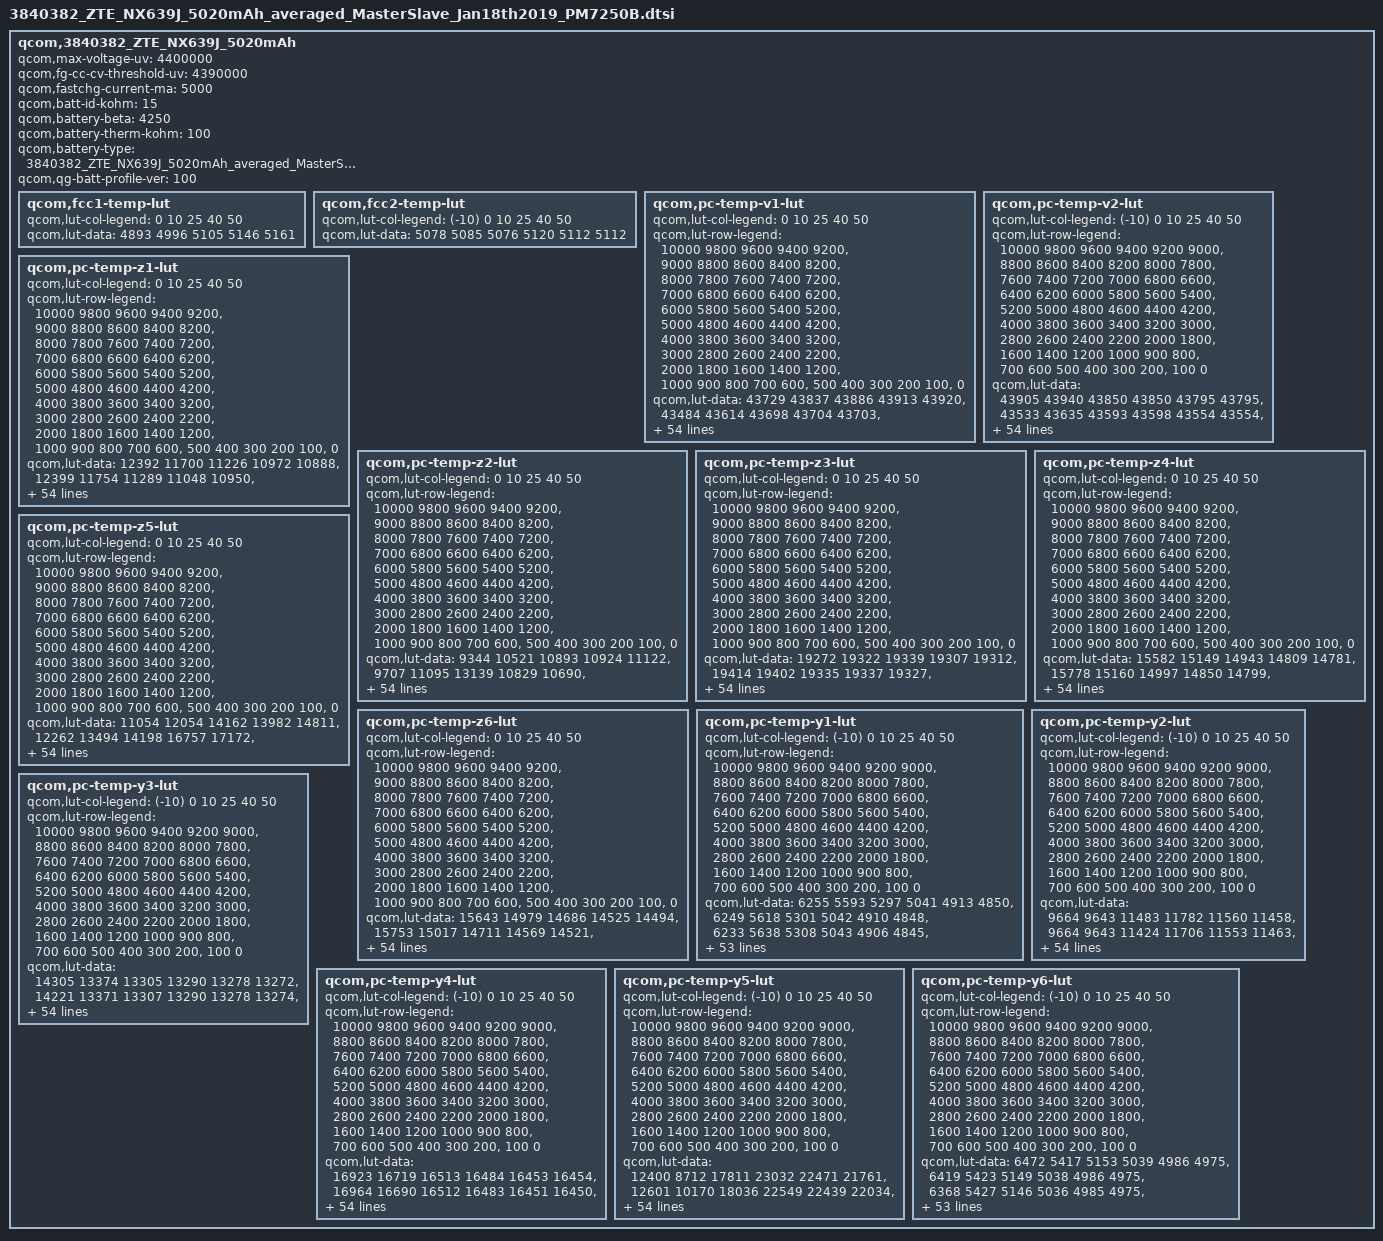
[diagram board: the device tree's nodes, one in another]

qcom,3840382_ZTE_NX639J_5020mAh {
    /* 3840382_ZTE_NX639J_5020mAh_averaged_MasterSlave_Jan18th2019 */
    qcom,max-voltage-uv = <4400000>;
    qcom,fg-cc-cv-threshold-uv = <4390000>;
    qcom,fastchg-current-ma = <5000>;
    qcom,batt-id-kohm = <15>;
    qcom,battery-beta = <4250>;
    qcom,battery-therm-kohm = <100>;
    qcom,battery-type = "3840382_ZTE_NX639J_5020mAh_averaged_MasterSlave_Jan18th2019";
    qcom,qg-batt-profile-ver = <100>;
    qcom,fcc1-temp-lut {
		qcom,lut-col-legend = <0 10 25 40 50>;
		qcom,lut-data = <4893 4996 5105 5146 5161>;
	};

	qcom,fcc2-temp-lut {
		qcom,lut-col-legend = <(-10) 0 10 25 40 50>;
		qcom,lut-data = <5078 5085 5076 5120 5112 5112>;
	};

	qcom,pc-temp-v1-lut {
		qcom,lut-col-legend = <0 10 25 40 50>;
		qcom,lut-row-legend = <10000 9800 9600 9400 9200>,
			<9000 8800 8600 8400 8200>,
			<8000 7800 7600 7400 7200>,
			<7000 6800 6600 6400 6200>,
			<6000 5800 5600 5400 5200>,
			<5000 4800 4600 4400 4200>,
			<4000 3800 3600 3400 3200>,
			<3000 2800 2600 2400 2200>,
			<2000 1800 1600 1400 1200>,
			<1000 900 800 700 600>,
			<500 400 300 200 100>,
			<0>;
		qcom,lut-data = <43729 43837 43886 43913 43920>,
			<43484 43614 43698 43704 43703>,
			<43234 43383 43471 43483 43490>,
			<42978 43142 43225 43257 43267>,
			<42731 42890 42983 43027 43040>,
			<42498 42647 42738 42791 42808>,
			<42275 42422 42498 42555 42574>,
			<42058 42205 42263 42319 42340>,
			<41849 41983 42034 42086 42107>,
			<41645 41759 41810 41854 41875>,
			<41454 41543 41591 41624 41645>,
			<41266 41344 41378 41399 41419>,
			<41065 41150 41178 41178 41199>,
			<40852 40948 40977 40963 40986>,
			<40623 40738 40752 40752 40777>,
			<40351 40513 40516 40547 40572>,
			<40063 40238 40300 40352 40374>,
			<39861 39979 40100 40170 40188>,
			<39730 39821 39922 39997 40009>,
			<39616 39713 39781 39832 39840>,
			<39494 39597 39650 39675 39682>,
			<39375 39454 39458 39484 39499>,
			<39256 39293 39164 39199 39236>,
			<39137 39096 38916 38937 38981>,
			<39019 38852 38766 38798 38828>,
			<38900 38666 38652 38698 38716>,
			<38779 38554 38562 38603 38613>,
			<38667 38469 38492 38509 38514>,
			<38563 38402 38426 38422 38421>,
			<38468 38347 38360 38340 38328>,
			<38400 38299 38298 38265 38240>,
			<38347 38254 38240 38195 38167>,
			<38301 38213 38186 38132 38106>,
			<38260 38176 38137 38072 38047>,
			<38223 38143 38093 38019 37987>,
			<38192 38108 38052 37970 37928>,
			<38169 38076 38012 37921 37869>,
			<38141 38041 37972 37876 37814>,
			<38092 37988 37917 37817 37747>,
			<38016 37907 37829 37729 37656>,
			<37925 37810 37723 37622 37550>,
			<37805 37698 37609 37509 37437>,
			<37667 37567 37478 37381 37308>,
			<37507 37404 37318 37224 37147>,
			<37356 37268 37173 37081 37008>,
			<37246 37177 37082 36991 36929>,
			<37209 37142 37055 36967 36907>,
			<37182 37119 37043 36951 36889>,
			<37158 37101 37025 36933 36869>,
			<37122 37067 36984 36885 36815>,
			<36951 36886 36775 36651 36558>,
			<36525 36462 36353 36221 36122>,
			<35958 35893 35785 35649 35548>,
			<35187 35119 35008 34867 34764>,
			<33977 33913 33804 33658 33549>,
			<30000 30000 30000 30000 30000>;
	};

	qcom,pc-temp-v2-lut {
		qcom,lut-col-legend = <(-10) 0 10 25 40 50>;
		qcom,lut-row-legend = <10000 9800 9600 9400 9200 9000>,
			<8800 8600 8400 8200 8000 7800>,
			<7600 7400 7200 7000 6800 6600>,
			<6400 6200 6000 5800 5600 5400>,
			<5200 5000 4800 4600 4400 4200>,
			<4000 3800 3600 3400 3200 3000>,
			<2800 2600 2400 2200 2000 1800>,
			<1600 1400 1200 1000 900 800>,
			<700 600 500 400 300 200>,
			<100 0>;
		qcom,lut-data = <43905 43940 43850 43850 43795 43795>,
			<43533 43635 43593 43598 43554 43554>,
			<43185 43346 43340 43350 43315 43315>,
			<42862 43075 43092 43106 43077 43078>,
			<42561 42822 42846 42865 42841 42845>,
			<42283 42575 42605 42625 42605 42611>,
			<42024 42329 42367 42389 42370 42375>,
			<41784 42091 42134 42154 42135 42139>,
			<41551 41868 41910 41924 41904 41907>,
			<41319 41655 41692 41698 41675 41679>,
			<41163 41448 41476 41473 41448 41453>,
			<41098 41241 41255 41246 41224 41231>,
			<41035 41042 41040 41029 41006 41012>,
			<40769 40868 40859 40847 40802 40801>,
			<40127 40715 40701 40685 40606 40595>,
			<39682 40502 40507 40481 40407 40395>,
			<39497 40092 40203 40182 40196 40202>,
			<39353 39679 39888 39913 39995 40017>,
			<39185 39473 39680 39774 39826 39847>,
			<39012 39337 39519 39671 39672 39684>,
			<38852 39191 39347 39512 39486 39493>,
			<38699 39022 39144 39251 39244 39256>,
			<38563 38857 38950 38998 39013 39028>,
			<38452 38705 38789 38815 38829 38842>,
			<38357 38561 38648 38659 38669 38678>,
			<38274 38435 38523 38528 38536 38542>,
			<38202 38322 38412 38416 38424 38429>,
			<38137 38224 38312 38316 38324 38327>,
			<38076 38141 38219 38225 38231 38232>,
			<38019 38069 38133 38143 38145 38144>,
			<37964 38007 38055 38067 38069 38067>,
			<37913 37954 37983 37996 38000 37997>,
			<37861 37905 37917 37929 37933 37930>,
			<37804 37857 37858 37866 37869 37867>,
			<37746 37812 37805 37806 37805 37802>,
			<37685 37765 37759 37749 37724 37713>,
			<37620 37717 37723 37693 37630 37597>,
			<37553 37664 37684 37631 37540 37491>,
			<37484 37605 37629 37562 37460 37403>,
			<37414 37539 37562 37486 37381 37319>,
			<37344 37459 37484 37405 37297 37236>,
			<37274 37358 37388 37312 37207 37149>,
			<37203 37249 37272 37193 37089 37036>,
			<37127 37137 37134 37056 36954 36902>,
			<37045 37041 37010 36929 36842 36788>,
			<36941 36957 36947 36884 36814 36758>,
			<36883 36919 36928 36869 36801 36748>,
			<36805 36879 36908 36850 36784 36733>,
			<36704 36825 36882 36820 36750 36702>,
			<36547 36728 36817 36741 36626 36589>,
			<36302 36514 36600 36469 36268 36251>,
			<35914 36102 36123 35979 35740 35741>,
			<35336 35497 35479 35326 35039 35066>,
			<34464 34628 34608 34410 33998 34109>,
			<32987 33305 33297 32979 32712 32726>,
			<28469 28082 28052 28053 28037 28038>;
	};

	qcom,pc-temp-z1-lut {
		qcom,lut-col-legend = <0 10 25 40 50>;
		qcom,lut-row-legend = <10000 9800 9600 9400 9200>,
			<9000 8800 8600 8400 8200>,
			<8000 7800 7600 7400 7200>,
			<7000 6800 6600 6400 6200>,
			<6000 5800 5600 5400 5200>,
			<5000 4800 4600 4400 4200>,
			<4000 3800 3600 3400 3200>,
			<3000 2800 2600 2400 2200>,
			<2000 1800 1600 1400 1200>,
			<1000 900 800 700 600>,
			<500 400 300 200 100>,
			<0>;
		qcom,lut-data = <12392 11700 11226 10972 10888>,
			<12399 11754 11289 11048 10950>,
			<12398 11782 11290 11047 10954>,
			<12395 11778 11285 11049 10954>,
			<12393 11759 11281 11048 10953>,
			<12395 11748 11277 11042 10950>,
			<12398 11747 11271 11035 10946>,
			<12394 11746 11264 11030 10943>,
			<12387 11747 11258 11025 10940>,
			<12380 11751 11257 11022 10938>,
			<12378 11753 11257 11019 10937>,
			<12378 11743 11257 11017 10937>,
			<12371 11726 11256 11019 10937>,
			<12353 11706 11254 11022 10937>,
			<12331 11680 11246 11021 10937>,
			<12310 11669 11232 11015 10937>,
			<12289 11669 11228 11012 10938>,
			<12277 11668 11229 11013 10939>,
			<12272 11671 11231 11015 10939>,
			<12268 11678 11234 11017 10940>,
			<12258 11683 11239 11019 10942>,
			<12242 11687 11242 11020 10942>,
			<12230 11691 11244 11021 10943>,
			<12225 11693 11246 11023 10943>,
			<12222 11691 11249 11024 10945>,
			<12227 11690 11253 11026 10947>,
			<12238 11690 11258 11028 10949>,
			<12247 11691 11265 11031 10951>,
			<12252 11694 11270 11034 10954>,
			<12257 11700 11273 11037 10957>,
			<12259 11706 11276 11041 10960>,
			<12258 11709 11276 11044 10964>,
			<12257 11712 11276 11047 10968>,
			<12267 11717 11277 11051 10972>,
			<12287 11727 11286 11055 10975>,
			<12294 11734 11297 11061 10978>,
			<12301 11744 11298 11065 10980>,
			<12306 11756 11296 11069 10983>,
			<12309 11763 11296 11072 10986>,
			<12317 11776 11302 11075 10990>,
			<12322 11782 11308 11077 10993>,
			<12339 11776 11310 11081 10996>,
			<12349 11771 11314 11087 10999>,
			<12370 11881 11323 11092 11003>,
			<12380 11852 11330 11096 11007>,
			<12366 11804 11331 11098 11009>,
			<12362 11800 11327 11103 11009>,
			<12389 11808 11336 11103 11012>,
			<12373 11793 11332 11105 11015>,
			<12348 11821 11334 11110 11019>,
			<12378 11828 11339 11115 11024>,
			<12406 11824 11353 11121 11032>,
			<12413 11876 11377 11131 11038>,
			<12450 11875 11389 11147 11054>,
			<12450 11875 11389 11147 11054>,
			<12450 11875 11389 11147 11054>;
	};

	qcom,pc-temp-z2-lut {
		qcom,lut-col-legend = <0 10 25 40 50>;
		qcom,lut-row-legend = <10000 9800 9600 9400 9200>,
			<9000 8800 8600 8400 8200>,
			<8000 7800 7600 7400 7200>,
			<7000 6800 6600 6400 6200>,
			<6000 5800 5600 5400 5200>,
			<5000 4800 4600 4400 4200>,
			<4000 3800 3600 3400 3200>,
			<3000 2800 2600 2400 2200>,
			<2000 1800 1600 1400 1200>,
			<1000 900 800 700 600>,
			<500 400 300 200 100>,
			<0>;
		qcom,lut-data = <9344 10521 10893 10924 11122>,
			<9707 11095 13139 10829 10690>,
			<9815 11376 12742 10880 10780>,
			<10143 11290 12028 10924 10844>,
			<10345 10830 11482 10932 10868>,
			<10350 10566 10979 10880 10820>,
			<10353 10641 10781 10811 10750>,
			<10354 10750 10967 10750 10695>,
			<10353 10724 11188 10693 10642>,
			<10351 10563 11185 10681 10623>,
			<10345 10473 11129 10690 10627>,
			<10335 10477 11058 10696 10631>,
			<10323 10484 10867 10703 10586>,
			<10301 10491 10707 10716 10509>,
			<10277 10504 10723 10729 10495>,
			<10254 10520 10761 10746 10525>,
			<10233 10549 10774 10753 10553>,
			<10230 10585 10772 10691 10566>,
			<10253 10621 10771 10615 10578>,
			<10282 10660 10793 10625 10602>,
			<10304 10686 10833 10687 10643>,
			<10325 10703 10851 10737 10660>,
			<10345 10713 10859 10782 10651>,
			<10362 10712 10863 10812 10641>,
			<10378 10701 10836 10767 10649>,
			<10397 10695 10792 10660 10677>,
			<10422 10708 10783 10632 10706>,
			<10446 10726 10794 10665 10736>,
			<10468 10728 10811 10714 10771>,
			<10490 10728 10848 10785 10833>,
			<10510 10728 10893 10865 10905>,
			<10527 10733 10918 10883 10888>,
			<10545 10745 10937 10860 10674>,
			<10573 10760 10943 10839 10529>,
			<10603 10783 10943 10821 10544>,
			<10570 10803 10942 10803 10578>,
			<10229 10817 10949 10815 10617>,
			<9930 10829 10972 10874 10672>,
			<10035 10844 10998 10930 10721>,
			<10314 10863 11036 10980 10762>,
			<10431 10885 11066 11015 10795>,
			<10424 10912 11075 11000 10811>,
			<10423 10944 11081 10968 10821>,
			<10485 10978 11091 10973 10837>,
			<10357 11243 11160 10985 10850>,
			<10423 17295 11253 10985 10828>,
			<10595 11767 11243 10965 10816>,
			<10419 11943 11195 10987 10839>,
			<10440 11686 11234 10998 10879>,
			<10396 11827 11279 11092 11075>,
			<10252 11537 11384 11105 10861>,
			<10053 11168 11382 10885 10617>,
			<9945 11270 11354 10786 10548>,
			<9751 16042 11240 10717 10470>,
			<9751 16042 11240 10717 10470>,
			<9751 16042 11240 10717 10470>;
	};

	qcom,pc-temp-z3-lut {
		qcom,lut-col-legend = <0 10 25 40 50>;
		qcom,lut-row-legend = <10000 9800 9600 9400 9200>,
			<9000 8800 8600 8400 8200>,
			<8000 7800 7600 7400 7200>,
			<7000 6800 6600 6400 6200>,
			<6000 5800 5600 5400 5200>,
			<5000 4800 4600 4400 4200>,
			<4000 3800 3600 3400 3200>,
			<3000 2800 2600 2400 2200>,
			<2000 1800 1600 1400 1200>,
			<1000 900 800 700 600>,
			<500 400 300 200 100>,
			<0>;
		qcom,lut-data = <19272 19322 19339 19307 19312>,
			<19414 19402 19335 19337 19327>,
			<19502 19462 19372 19362 19347>,
			<19636 19501 19414 19375 19361>,
			<19705 19539 19427 19381 19369>,
			<19701 19555 19432 19384 19372>,
			<19694 19549 19437 19385 19373>,
			<19687 19541 19446 19385 19374>,
			<19680 19539 19454 19385 19374>,
			<19674 19540 19453 19383 19374>,
			<19668 19539 19447 19379 19371>,
			<19660 19537 19440 19376 19367>,
			<19656 19532 19426 19373 19360>,
			<19656 19524 19414 19372 19353>,
			<19659 19511 19411 19369 19350>,
			<19679 19504 19408 19365 19348>,
			<19712 19506 19405 19361 19347>,
			<19719 19508 19399 19355 19344>,
			<19688 19500 19392 19349 19341>,
			<19652 19481 19389 19346 19338>,
			<19636 19471 19386 19344 19334>,
			<19625 19476 19387 19343 19332>,
			<19621 19484 19395 19347 19332>,
			<19624 19492 19400 19351 19332>,
			<19629 19500 19397 19346 19327>,
			<19632 19504 19391 19333 19316>,
			<19638 19504 19386 19329 19312>,
			<19641 19504 19382 19330 19317>,
			<19640 19503 19381 19331 19325>,
			<19637 19500 19383 19338 19340>,
			<19634 19496 19386 19350 19361>,
			<19624 19492 19390 19357 19365>,
			<19613 19487 19396 19363 19358>,
			<19603 19484 19398 19365 19350>,
			<19591 19480 19398 19362 19345>,
			<19556 19477 19397 19357 19341>,
			<19403 19473 19395 19353 19338>,
			<19272 19469 19390 19348 19335>,
			<19263 19467 19386 19345 19333>,
			<19261 19465 19384 19343 19330>,
			<19261 19462 19382 19341 19329>,
			<19261 19454 19379 19340 19329>,
			<19261 19445 19377 19339 19330>,
			<19260 19441 19374 19339 19334>,
			<19261 19383 19367 19336 19335>,
			<19260 19279 19356 19330 19325>,
			<19260 19293 19355 19328 19320>,
			<19260 19285 19336 19324 19316>,
			<19260 19268 19331 19322 19314>,
			<19260 19267 19332 19316 19303>,
			<19261 19260 19327 19319 19323>,
			<19262 19261 19320 19333 19334>,
			<19263 19275 19320 19336 19335>,
			<19265 19273 19318 19336 19335>,
			<19265 19273 19318 19336 19335>,
			<19265 19273 19318 19336 19335>;
	};

	qcom,pc-temp-z4-lut {
		qcom,lut-col-legend = <0 10 25 40 50>;
		qcom,lut-row-legend = <10000 9800 9600 9400 9200>,
			<9000 8800 8600 8400 8200>,
			<8000 7800 7600 7400 7200>,
			<7000 6800 6600 6400 6200>,
			<6000 5800 5600 5400 5200>,
			<5000 4800 4600 4400 4200>,
			<4000 3800 3600 3400 3200>,
			<3000 2800 2600 2400 2200>,
			<2000 1800 1600 1400 1200>,
			<1000 900 800 700 600>,
			<500 400 300 200 100>,
			<0>;
		qcom,lut-data = <15582 15149 14943 14809 14781>,
			<15778 15160 14997 14850 14799>,
			<15747 15154 14969 14870 14828>,
			<15577 15116 14921 14838 14807>,
			<15421 15017 14881 14809 14785>,
			<15319 14934 14841 14784 14765>,
			<15233 14879 14804 14761 14746>,
			<15161 14833 14762 14742 14729>,
			<15099 14803 14724 14725 14714>,
			<15046 14780 14703 14711 14702>,
			<15003 14761 14688 14697 14690>,
			<14967 14744 14681 14687 14682>,
			<14937 14730 14682 14681 14680>,
			<14913 14721 14685 14677 14678>,
			<14891 14714 14683 14672 14675>,
			<14868 14710 14681 14668 14668>,
			<14846 14708 14679 14664 14662>,
			<14830 14706 14675 14660 14657>,
			<14818 14701 14670 14657 14654>,
			<14807 14690 14660 14654 14652>,
			<14794 14680 14649 14652 14651>,
			<14781 14672 14657 14654 14652>,
			<14766 14666 14719 14710 14701>,
			<14748 14679 14765 14767 14759>,
			<14730 14729 14774 14773 14768>,
			<14720 14756 14779 14774 14771>,
			<14712 14753 14777 14772 14770>,
			<14710 14747 14764 14762 14756>,
			<14712 14739 14749 14746 14733>,
			<14717 14726 14734 14726 14706>,
			<14717 14714 14719 14703 14674>,
			<14713 14703 14704 14685 14662>,
			<14709 14694 14690 14669 14658>,
			<14707 14685 14680 14661 14656>,
			<14705 14676 14673 14660 14656>,
			<14721 14669 14667 14660 14656>,
			<14875 14662 14664 14660 14657>,
			<15011 14657 14661 14659 14657>,
			<15012 14655 14661 14659 14658>,
			<14999 14654 14666 14666 14666>,
			<14987 14654 14670 14674 14674>,
			<14980 14656 14667 14671 14671>,
			<14969 14658 14661 14666 14664>,
			<14951 14656 14661 14666 14664>,
			<14881 14688 14656 14662 14659>,
			<14851 14771 14639 14645 14644>,
			<14849 14755 14632 14639 14642>,
			<14846 14758 14642 14631 14632>,
			<14843 14771 14639 14618 14618>,
			<14836 14770 14635 14622 14623>,
			<14837 14782 14655 14642 14632>,
			<14851 14792 14674 14637 14632>,
			<14861 14784 14676 14637 14634>,
			<14873 14792 14684 14640 14637>,
			<14873 14792 14684 14640 14637>,
			<14873 14792 14684 14640 14637>;
	};

	qcom,pc-temp-z5-lut {
		qcom,lut-col-legend = <0 10 25 40 50>;
		qcom,lut-row-legend = <10000 9800 9600 9400 9200>,
			<9000 8800 8600 8400 8200>,
			<8000 7800 7600 7400 7200>,
			<7000 6800 6600 6400 6200>,
			<6000 5800 5600 5400 5200>,
			<5000 4800 4600 4400 4200>,
			<4000 3800 3600 3400 3200>,
			<3000 2800 2600 2400 2200>,
			<2000 1800 1600 1400 1200>,
			<1000 900 800 700 600>,
			<500 400 300 200 100>,
			<0>;
		qcom,lut-data = <11054 12054 14162 13982 14811>,
			<12262 13494 14198 16757 17172>,
			<13276 14899 15689 18680 18910>,
			<14678 16344 17583 19757 20502>,
			<15560 18405 18841 20414 21477>,
			<15791 19495 19831 20802 21908>,
			<15947 18910 21195 21167 22277>,
			<16175 18066 23874 21672 22864>,
			<16491 18626 26769 22279 23629>,
			<16761 20988 28594 23041 24505>,
			<17008 23147 30039 24102 25783>,
			<17238 24789 30695 25196 26621>,
			<17329 26012 29623 26286 26027>,
			<17531 26040 28354 27369 24837>,
			<17920 25248 29128 28383 24784>,
			<20350 25173 31021 29747 26397>,
			<24644 27690 31440 30412 28180>,
			<25801 30404 29583 28925 29569>,
			<23194 30101 28032 27104 30798>,
			<20634 27916 30101 27799 31599>,
			<20535 26847 35525 30456 32224>,
			<20965 32770 43094 33245 32427>,
			<21589 43226 56260 36617 31749>,
			<23838 53293 63628 38937 30332>,
			<27740 64717 55530 34789 26840>,
			<33201 65535 41599 24689 20451>,
			<41573 65535 34468 20587 18046>,
			<48406 59133 29760 19495 17891>,
			<53404 54109 28018 19049 17989>,
			<57120 49571 28259 20135 22438>,
			<57097 46259 28846 22940 31092>,
			<52948 43850 30745 26772 33303>,
			<47809 42236 36075 33408 33234>,
			<43609 42171 41551 38855 33233>,
			<39063 42793 47810 42260 35147>,
			<32515 43222 52539 44497 37878>,
			<20556 42963 53047 44270 38237>,
			<11895 42572 52630 42210 37906>,
			<11542 43206 51767 39739 37264>,
			<11549 45965 49257 36584 33472>,
			<11560 47590 45889 33292 29175>,
			<11590 40725 42265 30699 28148>,
			<11639 34273 38888 28759 27753>,
			<11723 35731 37531 28226 29956>,
			<12151 25798 36840 28193 31413>,
			<12288 12990 36444 28369 27342>,
			<12253 13365 37097 27776 23902>,
			<12236 13000 23813 27311 24649>,
			<12202 12432 22119 31611 30152>,
			<12227 12421 23535 26969 22271>,
			<12324 12331 20262 21473 26310>,
			<12332 12293 16911 23553 26555>,
			<12193 12607 16390 23329 24558>,
			<12100 12428 15502 21318 21600>,
			<12100 12428 15502 21318 21600>,
			<12100 12428 15502 21318 21600>;
	};

	qcom,pc-temp-z6-lut {
		qcom,lut-col-legend = <0 10 25 40 50>;
		qcom,lut-row-legend = <10000 9800 9600 9400 9200>,
			<9000 8800 8600 8400 8200>,
			<8000 7800 7600 7400 7200>,
			<7000 6800 6600 6400 6200>,
			<6000 5800 5600 5400 5200>,
			<5000 4800 4600 4400 4200>,
			<4000 3800 3600 3400 3200>,
			<3000 2800 2600 2400 2200>,
			<2000 1800 1600 1400 1200>,
			<1000 900 800 700 600>,
			<500 400 300 200 100>,
			<0>;
		qcom,lut-data = <15643 14979 14686 14525 14494>,
			<15753 15017 14711 14569 14521>,
			<15746 15032 14710 14586 14543>,
			<15699 15022 14709 14580 14542>,
			<15647 14985 14702 14574 14539>,
			<15583 14949 14680 14564 14533>,
			<15511 14915 14661 14553 14524>,
			<15454 14882 14645 14544 14517>,
			<15406 14861 14630 14536 14511>,
			<15364 14846 14618 14528 14505>,
			<15328 14832 14607 14519 14498>,
			<15295 14820 14598 14512 14492>,
			<15265 14807 14591 14509 14487>,
			<15236 14791 14585 14506 14483>,
			<15214 14772 14579 14503 14478>,
			<15203 14761 14573 14497 14475>,
			<15194 14758 14568 14492 14471>,
			<15181 14755 14563 14487 14468>,
			<15155 14748 14559 14483 14464>,
			<15128 14735 14553 14480 14462>,
			<15109 14729 14549 14478 14459>,
			<15094 14730 14553 14479 14459>,
			<15083 14734 14585 14506 14481>,
			<15074 14745 14608 14533 14505>,
			<15068 14773 14609 14532 14506>,
			<15066 14787 14610 14527 14504>,
			<15066 14786 14608 14523 14500>,
			<15067 14786 14602 14520 14497>,
			<15069 14784 14595 14516 14493>,
			<15072 14778 14591 14513 14491>,
			<15072 14772 14587 14509 14489>,
			<15066 14767 14584 14506 14486>,
			<15060 14762 14582 14503 14480>,
			<15055 14758 14580 14501 14476>,
			<15051 14754 14578 14499 14474>,
			<15046 14751 14576 14497 14472>,
			<15040 14749 14574 14495 14471>,
			<15035 14748 14573 14493 14469>,
			<15036 14749 14572 14492 14469>,
			<15037 14752 14575 14494 14471>,
			<15039 14754 14577 14497 14474>,
			<15043 14755 14576 14496 14473>,
			<15046 14756 14575 14494 14472>,
			<15047 14758 14576 14495 14474>,
			<15028 14748 14573 14493 14473>,
			<15019 14736 14563 14483 14462>,
			<15018 14735 14560 14480 14458>,
			<15018 14733 14555 14474 14452>,
			<15019 14733 14552 14468 14445>,
			<15019 14736 14552 14468 14443>,
			<15030 14742 14562 14479 14458>,
			<15044 14753 14569 14487 14466>,
			<15060 14764 14575 14491 14469>,
			<15086 14779 14584 14496 14474>,
			<15086 14779 14584 14496 14474>,
			<15086 14779 14584 14496 14474>;
	};

	qcom,pc-temp-y1-lut {
		qcom,lut-col-legend = <(-10) 0 10 25 40 50>;
		qcom,lut-row-legend = <10000 9800 9600 9400 9200 9000>,
			<8800 8600 8400 8200 8000 7800>,
			<7600 7400 7200 7000 6800 6600>,
			<6400 6200 6000 5800 5600 5400>,
			<5200 5000 4800 4600 4400 4200>,
			<4000 3800 3600 3400 3200 3000>,
			<2800 2600 2400 2200 2000 1800>,
			<1600 1400 1200 1000 900 800>,
			<700 600 500 400 300 200>,
			<100 0>;
		qcom,lut-data = <6255 5593 5297 5041 4913 4850>,
			<6249 5618 5301 5042 4910 4848>,
			<6233 5638 5308 5043 4906 4845>,
			<6213 5652 5314 5043 4903 4843>,
			<6196 5661 5319 5042 4900 4841>,
			<6189 5664 5321 5041 4897 4839>,
			<6183 5657 5319 5038 4895 4837>,
			<6174 5648 5317 5034 4893 4835>,
			<6168 5647 5314 5033 4891 4833>,
			<6158 5647 5308 5033 4888 4831>,
			<6153 5648 5304 5033 4887 4830>,
			<6176 5646 5301 5029 4885 4830>,
			<6204 5645 5299 5026 4884 4830>,
			<6206 5645 5299 5025 4883 4829>,
			<6196 5648 5302 5024 4882 4828>,
			<6192 5651 5305 5025 4882 4828>,
			<6202 5658 5309 5028 4883 4828>,
			<6214 5665 5312 5031 4883 4828>,
			<6211 5672 5313 5030 4883 4828>,
			<6198 5679 5312 5027 4881 4829>,
			<6192 5681 5312 5027 4881 4830>,
			<6191 5680 5314 5029 4882 4830>,
			<6191 5678 5316 5031 4883 4830>,
			<6186 5674 5315 5031 4883 4831>,
			<6177 5668 5312 5029 4883 4832>,
			<6174 5664 5310 5029 4884 4832>,
			<6175 5661 5309 5030 4886 4834>,
			<6175 5660 5309 5031 4888 4835>,
			<6186 5662 5310 5032 4890 4837>,
			<6214 5666 5312 5033 4892 4840>,
			<6222 5669 5312 5035 4894 4842>,
			<6204 5675 5312 5037 4895 4843>,
			<6188 5679 5312 5040 4897 4844>,
			<6197 5675 5314 5045 4901 4846>,
			<6218 5668 5319 5051 4904 4848>,
			<6224 5668 5320 5051 4904 4850>,
			<6213 5671 5317 5049 4903 4852>,
			<6198 5673 5314 5048 4903 4853>,
			<6184 5671 5315 5050 4906 4855>,
			<6171 5668 5315 5052 4910 4856>,
			<6170 5669 5316 5054 4912 4858>,
			<6181 5671 5318 5056 4913 4860>,
			<6185 5678 5322 5057 4915 4862>,
			<6187 5693 5333 5060 4918 4864>,
			<6226 5681 5336 5063 4923 4867>,
			<6194 5690 5332 5068 4927 4871>,
			<6222 5705 5329 5069 4929 4870>,
			<6266 5694 5331 5077 4927 4870>,
			<6235 5697 5333 5071 4929 4870>,
			<6224 5709 5337 5073 4931 4871>,
			<6246 5705 5346 5076 4933 4874>,
			<6277 5734 5349 5086 4936 4880>,
			<6286 5733 5363 5097 4949 4886>,
			<6371 5750 5382 5125 4961 4895>,
			<6371 5750 5382 5125 4961 4895>,
			<6371 5750 5382 5125 4961 4895>;
	};

	qcom,pc-temp-y2-lut {
		qcom,lut-col-legend = <(-10) 0 10 25 40 50>;
		qcom,lut-row-legend = <10000 9800 9600 9400 9200 9000>,
			<8800 8600 8400 8200 8000 7800>,
			<7600 7400 7200 7000 6800 6600>,
			<6400 6200 6000 5800 5600 5400>,
			<5200 5000 4800 4600 4400 4200>,
			<4000 3800 3600 3400 3200 3000>,
			<2800 2600 2400 2200 2000 1800>,
			<1600 1400 1200 1000 900 800>,
			<700 600 500 400 300 200>,
			<100 0>;
		qcom,lut-data = <9664 9643 11483 11782 11560 11458>,
			<9664 9643 11424 11706 11553 11463>,
			<9664 9643 11366 11627 11526 11450>,
			<9664 10059 11312 11553 11490 11425>,
			<9665 10521 11265 11490 11456 11397>,
			<9665 10707 11230 11448 11432 11373>,
			<9666 10718 11202 11420 11377 11314>,
			<9667 10724 11182 11400 11315 11246>,
			<9667 10734 11170 11387 11295 11224>,
			<9667 10748 11161 11377 11266 11212>,
			<9667 10768 11158 11370 11253 11202>,
			<9668 10806 11165 11364 11255 11182>,
			<9669 10859 11178 11359 11261 11163>,
			<9669 10942 11204 11355 11283 11160>,
			<9668 11073 11256 11353 11330 11165>,
			<9667 11130 11302 11362 11362 11175>,
			<9667 11116 11336 11444 11379 11194>,
			<9668 11100 11365 11555 11403 11224>,
			<9667 11116 11383 11661 11491 11308>,
			<9667 11157 11397 11762 11639 11437>,
			<9667 11187 11418 11776 11677 11474>,
			<9667 11205 11461 11702 11650 11473>,
			<9667 11219 11513 11646 11622 11472>,
			<9667 11070 11562 11653 11607 11479>,
			<9667 10721 11612 11672 11595 11491>,
			<9666 10559 11646 11698 11596 11500>,
			<9666 10214 11671 11745 11624 11515>,
			<9666 9887 11685 11787 11647 11532>,
			<9666 9821 11686 11821 11658 11553>,
			<9666 9787 11685 11847 11672 11580>,
			<9666 9765 11684 11861 11702 11606>,
			<9666 9746 11683 11875 11778 11632>,
			<9665 9733 11683 11881 11832 11665>,
			<9665 9726 11689 11858 11854 11730>,
			<9664 9720 11699 11829 11867 11788>,
			<9664 9715 11697 11826 11857 11761>,
			<9664 9709 11664 11829 11815 11651>,
			<9664 9703 11628 11827 11775 11592>,
			<9664 9698 11611 11798 11744 11578>,
			<9663 9694 11595 11767 11714 11570>,
			<9663 9689 11570 11751 11674 11552>,
			<9663 9685 11526 11729 11633 11525>,
			<9663 9681 11469 11703 11625 11516>,
			<9662 9678 11398 11644 11643 11512>,
			<9662 9675 11344 11596 11626 11486>,
			<9662 9673 11285 11495 11509 11293>,
			<9661 9672 11197 11502 11473 11235>,
			<9662 9670 11162 11455 11492 11239>,
			<9661 9669 11136 11423 11512 11276>,
			<9661 9667 11115 11436 11510 11230>,
			<9661 9666 11072 11372 11412 11208>,
			<9660 9665 10908 11247 11289 11130>,
			<9658 9663 10498 11103 11189 11009>,
			<9655 9661 10582 10969 11065 10831>,
			<9655 9661 10582 10969 11065 10831>,
			<9655 9661 10582 10969 11065 10831>;
	};

	qcom,pc-temp-y3-lut {
		qcom,lut-col-legend = <(-10) 0 10 25 40 50>;
		qcom,lut-row-legend = <10000 9800 9600 9400 9200 9000>,
			<8800 8600 8400 8200 8000 7800>,
			<7600 7400 7200 7000 6800 6600>,
			<6400 6200 6000 5800 5600 5400>,
			<5200 5000 4800 4600 4400 4200>,
			<4000 3800 3600 3400 3200 3000>,
			<2800 2600 2400 2200 2000 1800>,
			<1600 1400 1200 1000 900 800>,
			<700 600 500 400 300 200>,
			<100 0>;
		qcom,lut-data = <14305 13374 13305 13290 13278 13272>,
			<14221 13371 13307 13290 13278 13274>,
			<14141 13371 13308 13290 13278 13275>,
			<14066 13373 13310 13290 13278 13276>,
			<13999 13375 13312 13291 13279 13277>,
			<13941 13376 13313 13292 13280 13277>,
			<13894 13378 13313 13292 13280 13277>,
			<13851 13381 13314 13293 13281 13277>,
			<13790 13383 13316 13294 13281 13277>,
			<13710 13386 13321 13295 13281 13278>,
			<13665 13389 13324 13295 13281 13279>,
			<13655 13394 13324 13296 13282 13280>,
			<13647 13398 13325 13298 13282 13281>,
			<13630 13394 13327 13301 13284 13281>,
			<13603 13381 13331 13305 13288 13281>,
			<13588 13369 13333 13306 13289 13281>,
			<13582 13362 13330 13300 13287 13282>,
			<13579 13356 13326 13294 13286 13283>,
			<13579 13354 13323 13295 13286 13284>,
			<13580 13353 13320 13298 13287 13285>,
			<13581 13351 13317 13298 13287 13285>,
			<13582 13347 13314 13294 13284 13281>,
			<13583 13342 13310 13290 13281 13278>,
			<13587 13335 13306 13287 13279 13276>,
			<13596 13327 13302 13285 13278 13275>,
			<13606 13318 13300 13284 13277 13275>,
			<13619 13305 13300 13283 13277 13275>,
			<13633 13296 13300 13283 13276 13275>,
			<13647 13297 13300 13284 13276 13274>,
			<13662 13300 13300 13286 13275 13273>,
			<13681 13301 13300 13286 13275 13273>,
			<13705 13301 13301 13286 13276 13273>,
			<13731 13300 13301 13286 13276 13274>,
			<13758 13307 13301 13286 13277 13275>,
			<13787 13320 13299 13286 13278 13276>,
			<13819 13325 13299 13286 13278 13275>,
			<13853 13330 13302 13286 13277 13274>,
			<13892 13337 13305 13285 13276 13274>,
			<13934 13346 13305 13285 13276 13274>,
			<13981 13361 13305 13285 13276 13274>,
			<14029 13373 13306 13285 13277 13275>,
			<14079 13385 13306 13287 13277 13276>,
			<14134 13403 13306 13287 13277 13276>,
			<14192 13428 13302 13287 13276 13276>,
			<14238 13452 13298 13284 13274 13273>,
			<14239 13473 13300 13288 13280 13278>,
			<14298 13499 13305 13291 13282 13281>,
			<14343 13535 13311 13295 13286 13283>,
			<14414 13573 13319 13300 13288 13285>,
			<14478 13614 13325 13304 13287 13283>,
			<14548 13658 13326 13301 13283 13280>,
			<14641 13716 13323 13302 13284 13282>,
			<14955 13834 13327 13307 13288 13284>,
			<15603 13997 13351 13317 13293 13289>,
			<15603 13997 13351 13317 13293 13289>,
			<15603 13997 13351 13317 13293 13289>;
	};

	qcom,pc-temp-y4-lut {
		qcom,lut-col-legend = <(-10) 0 10 25 40 50>;
		qcom,lut-row-legend = <10000 9800 9600 9400 9200 9000>,
			<8800 8600 8400 8200 8000 7800>,
			<7600 7400 7200 7000 6800 6600>,
			<6400 6200 6000 5800 5600 5400>,
			<5200 5000 4800 4600 4400 4200>,
			<4000 3800 3600 3400 3200 3000>,
			<2800 2600 2400 2200 2000 1800>,
			<1600 1400 1200 1000 900 800>,
			<700 600 500 400 300 200>,
			<100 0>;
		qcom,lut-data = <16923 16719 16513 16484 16453 16454>,
			<16964 16690 16512 16483 16451 16450>,
			<17007 16669 16513 16482 16450 16448>,
			<17047 16655 16515 16481 16449 16447>,
			<17075 16646 16518 16480 16449 16446>,
			<17086 16644 16521 16480 16449 16446>,
			<17077 16649 16525 16480 16450 16447>,
			<17065 16659 16530 16481 16451 16448>,
			<17083 16672 16534 16483 16453 16449>,
			<17178 16690 16539 16488 16457 16451>,
			<17282 16709 16546 16493 16461 16452>,
			<17403 16724 16555 16498 16465 16454>,
			<17500 16744 16569 16504 16470 16458>,
			<17393 16807 16599 16520 16475 16462>,
			<16999 16938 16653 16546 16481 16467>,
			<16816 16985 16676 16559 16488 16472>,
			<16814 16807 16663 16563 16497 16477>,
			<16813 16618 16642 16568 16509 16484>,
			<16801 16606 16624 16594 16529 16497>,
			<16770 16611 16604 16639 16552 16515>,
			<16742 16612 16580 16641 16555 16519>,
			<16717 16592 16536 16570 16525 16504>,
			<16700 16571 16499 16504 16491 16485>,
			<16695 16569 16491 16480 16469 16467>,
			<16692 16573 16488 16465 16451 16450>,
			<16690 16579 16486 16463 16448 16447>,
			<16689 16594 16485 16464 16450 16448>,
			<16689 16605 16484 16466 16453 16449>,
			<16690 16606 16485 16468 16458 16454>,
			<16694 16606 16487 16471 16466 16461>,
			<16696 16607 16487 16476 16474 16469>,
			<16696 16613 16486 16482 16483 16477>,
			<16697 16619 16486 16486 16490 16484>,
			<16700 16618 16487 16488 16493 16492>,
			<16704 16617 16491 16490 16495 16498>,
			<16709 16617 16495 16488 16490 16491>,
			<16713 16622 16500 16484 16469 16468>,
			<16718 16628 16504 16479 16458 16455>,
			<16726 16632 16506 16473 16455 16452>,
			<16737 16636 16507 16469 16454 16451>,
			<16751 16636 16507 16470 16456 16454>,
			<16769 16632 16505 16474 16462 16461>,
			<16793 16626 16503 16474 16460 16460>,
			<16820 16619 16500 16473 16453 16451>,
			<16826 16620 16500 16462 16442 16435>,
			<16777 16622 16499 16473 16450 16447>,
			<16798 16636 16508 16484 16465 16465>,
			<16810 16661 16521 16503 16490 16494>,
			<16826 16696 16548 16532 16521 16525>,
			<16839 16732 16584 16566 16515 16518>,
			<16842 16738 16584 16538 16465 16462>,
			<16849 16727 16548 16518 16462 16454>,
			<16958 16731 16573 16535 16470 16456>,
			<17313 16773 16600 16570 16500 16474>,
			<17313 16773 16600 16570 16500 16474>,
			<17313 16773 16600 16570 16500 16474>;
	};

	qcom,pc-temp-y5-lut {
		qcom,lut-col-legend = <(-10) 0 10 25 40 50>;
		qcom,lut-row-legend = <10000 9800 9600 9400 9200 9000>,
			<8800 8600 8400 8200 8000 7800>,
			<7600 7400 7200 7000 6800 6600>,
			<6400 6200 6000 5800 5600 5400>,
			<5200 5000 4800 4600 4400 4200>,
			<4000 3800 3600 3400 3200 3000>,
			<2800 2600 2400 2200 2000 1800>,
			<1600 1400 1200 1000 900 800>,
			<700 600 500 400 300 200>,
			<100 0>;
		qcom,lut-data = <12400 8712 17811 23032 22471 21761>,
			<12601 10170 18036 22549 22439 22034>,
			<12828 12473 18080 22028 22149 22164>,
			<13079 14834 17983 21501 21724 22178>,
			<13352 16694 17783 20998 21288 22098>,
			<13646 17498 17520 20549 20957 21940>,
			<14052 17443 17023 20162 20642 20750>,
			<14400 17298 16534 19753 20258 19218>,
			<14191 17604 16607 19165 19628 18905>,
			<13190 18441 17159 18394 18411 19157>,
			<12727 18824 17440 17916 17482 19113>,
			<15962 18169 17169 17607 16816 18641>,
			<19934 17398 16814 17371 16396 18055>,
			<19266 18034 16734 17120 16612 17433>,
			<15555 20365 16766 16620 17277 16748>,
			<13861 21587 16971 16207 17449 16336>,
			<14011 21776 19877 15683 16384 16100>,
			<14219 21912 23306 15320 15390 15991>,
			<14340 22266 24120 16203 15448 15979>,
			<14437 22869 24502 18512 15787 16023>,
			<14446 23070 24597 20753 16640 16478>,
			<14046 22670 24450 23419 20147 18403>,
			<13557 21913 24149 24929 22906 20445>,
			<13328 20194 22825 23802 23178 21775>,
			<13167 17267 20142 21684 23266 22797>,
			<13128 15287 19242 20741 23020 22860>,
			<13141 13801 19432 20301 21777 21902>,
			<13153 12967 19647 20333 20514 20780>,
			<13129 12932 19733 21695 19569 19326>,
			<13075 12928 19798 23508 18845 17868>,
			<13084 12934 19991 24223 18821 17685>,
			<13315 12955 20789 24622 19272 17880>,
			<13504 12939 21409 24785 19946 18202>,
			<13477 13141 20965 24812 21529 19622>,
			<13398 13570 20002 24830 23150 21361>,
			<13325 13728 19999 24960 23384 21941>,
			<13248 13879 22116 25268 23359 22245>,
			<13187 14008 23756 25344 23252 22326>,
			<13128 14276 23490 24231 22777 22031>,
			<13072 14633 22993 22925 22088 21649>,
			<13083 14653 22783 22622 21333 21403>,
			<13171 14392 22532 22599 20656 21215>,
			<13292 14112 21625 22362 21194 22527>,
			<13480 13894 18980 21214 21171 23277>,
			<13866 13870 16462 19594 18739 20058>,
			<14241 13832 16669 19828 20060 19740>,
			<14459 13926 17547 19195 19483 19311>,
			<14744 14080 18019 18952 19195 18282>,
			<15133 14229 19131 19383 18873 17531>,
			<15449 14767 19607 19773 18847 16880>,
			<15717 15160 20011 19853 19765 19136>,
			<15391 14715 18909 20646 20507 20219>,
			<13811 14567 17237 20162 22706 21026>,
			<12045 14211 20274 20853 25602 26101>,
			<12045 14211 20274 20853 25602 26101>,
			<12045 14211 20274 20853 25602 26101>;
	};

	qcom,pc-temp-y6-lut {
		qcom,lut-col-legend = <(-10) 0 10 25 40 50>;
		qcom,lut-row-legend = <10000 9800 9600 9400 9200 9000>,
			<8800 8600 8400 8200 8000 7800>,
			<7600 7400 7200 7000 6800 6600>,
			<6400 6200 6000 5800 5600 5400>,
			<5200 5000 4800 4600 4400 4200>,
			<4000 3800 3600 3400 3200 3000>,
			<2800 2600 2400 2200 2000 1800>,
			<1600 1400 1200 1000 900 800>,
			<700 600 500 400 300 200>,
			<100 0>;
		qcom,lut-data = <6472 5417 5153 5039 4986 4975>,
			<6419 5423 5149 5038 4986 4975>,
			<6368 5427 5146 5036 4985 4975>,
			<6320 5429 5143 5034 4985 4975>,
			<6274 5429 5140 5033 4985 4975>,
			<6231 5429 5137 5032 4985 4975>,
			<6189 5426 5135 5032 4986 4975>,
			<6151 5422 5133 5031 4986 4976>,
			<6119 5421 5133 5032 4987 4976>,
			<6089 5422 5134 5032 4988 4977>,
			<6078 5423 5136 5033 4989 4979>,
			<6096 5424 5137 5035 4990 4980>,
			<6119 5425 5139 5037 4991 4981>,
			<6083 5433 5146 5043 4994 4982>,
			<5954 5455 5162 5053 4998 4984>,
			<5890 5462 5169 5056 5001 4985>,
			<5887 5411 5163 5054 5003 4987>,
			<5885 5356 5155 5052 5006 4990>,
			<5880 5353 5148 5059 5011 4995>,
			<5872 5355 5141 5073 5018 5001>,
			<5866 5355 5132 5074 5018 5002>,
			<5861 5348 5117 5051 5007 4994>,
			<5858 5338 5104 5029 4995 4986>,
			<5859 5332 5099 5020 4987 4979>,
			<5865 5327 5095 5014 4981 4974>,
			<5873 5325 5095 5013 4980 4973>,
			<5882 5326 5095 5014 4981 4973>,
			<5893 5327 5096 5015 4981 4974>,
			<5905 5330 5097 5016 4983 4975>,
			<5917 5336 5098 5019 4985 4976>,
			<5932 5343 5100 5022 4987 4978>,
			<5950 5352 5102 5024 4991 4981>,
			<5969 5361 5103 5026 4993 4984>,
			<5990 5370 5105 5028 4995 4987>,
			<6014 5380 5107 5028 4996 4989>,
			<6039 5392 5110 5028 4995 4987>,
			<6068 5405 5116 5028 4988 4980>,
			<6100 5420 5121 5028 4985 4976>,
			<6134 5437 5124 5027 4985 4976>,
			<6172 5457 5127 5026 4985 4976>,
			<6212 5476 5130 5028 4986 4977>,
			<6257 5496 5134 5032 4988 4980>,
			<6306 5519 5137 5035 4988 4980>,
			<6359 5548 5140 5036 4986 4978>,
			<6402 5577 5143 5034 4982 4972>,
			<6400 5597 5148 5043 4990 4979>,
			<6448 5629 5158 5050 4996 4987>,
			<6496 5668 5172 5059 5005 4997>,
			<6551 5712 5191 5073 5016 5007>,
			<6607 5761 5210 5087 5013 5004>,
			<6670 5802 5216 5078 4997 4986>,
			<6750 5851 5213 5078 4998 4985>,
			<7058 5955 5248 5096 5005 4988>,
			<7716 6101 5305 5124 5019 4999>,
			<7716 6101 5305 5124 5019 4999>,
			<7716 6101 5305 5124 5019 4999>;
	};
};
